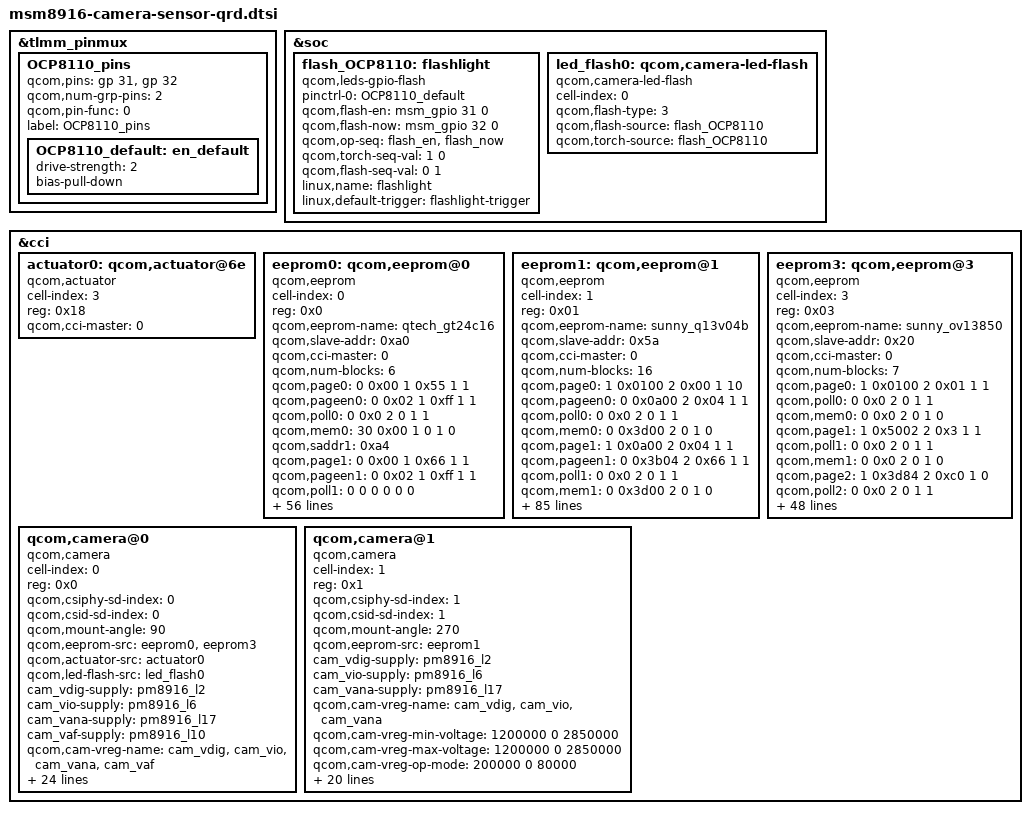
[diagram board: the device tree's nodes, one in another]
/*
 * Copyright (c) 2014, The Linux Foundation. All rights reserved.
 *
 * This program is free software; you can redistribute it and/or modify
 * it under the terms of the GNU General Public License version 2 and
 * only version 2 as published by the Free Software Foundation.
 *
 * This program is distributed in the hope that it will be useful,
 * but WITHOUT ANY WARRANTY; without even the implied warranty of
 * MERCHANTABILITY or FITNESS FOR A PARTICULAR PURPOSE.  See the
 * GNU General Public License for more details.
 */

&tlmm_pinmux {
	OCP8110_pins {
		qcom,pins = <&gp 31>, <&gp 32>;
		qcom,num-grp-pins = <2>;
		qcom,pin-func = <0>;
		label = "OCP8110_pins";
		OCP8110_default: en_default {
			  drive-strength = <2>;
			  bias-pull-down;
		};
	};
};

&soc {
	flash_OCP8110:flashlight {
		compatible = "qcom,leds-gpio-flash";
		status = "okay";
		pinctrl-names = "flash_default";
		pinctrl-0 = <&OCP8110_default>;
		qcom,flash-en = <&msm_gpio 31 0>;
		qcom,flash-now = <&msm_gpio 32 0>;
		qcom,op-seq = "flash_en", "flash_now";
		qcom,torch-seq-val = <1 0>;//1//1.0
		qcom,flash-seq-val = <0 1>;//1//1.1
		linux,name = "flashlight";
		linux,default-trigger = "flashlight-trigger";
	};

	led_flash0: qcom,camera-led-flash {
		cell-index = <0>;
		compatible = "qcom,camera-led-flash";
		qcom,flash-type = <3>;
		qcom,flash-source = <&flash_OCP8110>;
		qcom,torch-source = <&flash_OCP8110>;
	};
};

&cci {
	actuator0: qcom,actuator@6e {
		cell-index = <3>;
		reg = <0x18>;
		compatible = "qcom,actuator";
		qcom,cci-master = <0>;
	};

	eeprom0: qcom,eeprom@0 {
		cell-index = <0>;
		reg = <0x0>;
		qcom,eeprom-name = "qtech_gt24c16";
		compatible = "qcom,eeprom";
		qcom,slave-addr = <0xa0>;
		qcom,cci-master = <0>;
		
		qcom,num-blocks = <6>;
		
		qcom,page0 = <0 0x00 1 0x55 1 1>;
		qcom,pageen0 = <0 0x02 1 0xff 1 1>;
		qcom,poll0 = <0 0x0 2 0 1 1>;
		qcom,mem0 = <30 0x00 1 0 1 0>;

		qcom,saddr1 = <0xa4>;
		qcom,page1 = <0 0x00 1 0x66 1 1>;
		qcom,pageen1 = <0 0x02 1 0xff 1 1>;
		qcom,poll1 = <0 0 0 0 0 0>;
		qcom,mem1 = <255 0x00 1 0 1 0>;
		
		qcom,saddr2 = <0xa6>;
		qcom,page2 = <0 0x00 1 0x77 1 1>;
		qcom,pageen2 = <0 0x02 1 0xff 1 1>;
		qcom,poll2 = <0 0 0 0 0 0>;
		qcom,mem2 = <255 0x00 1 0 1 0>;

		qcom,saddr3 = <0xa8>;
		qcom,page3 = <0 0x00 1 0x88 1 1>;
		qcom,pageen3 = <0 0x02 1 0xff 1 1>;
		qcom,poll3 = <0 0 0 0 0 0>;
		qcom,mem3 = <255 0x00 1 0 1 0>;
		
		qcom,saddr4 = <0xaa>;
		qcom,page4 = <0 0x00 1 0x99 1 1>;
		qcom,pageen4 = <0 0x02 1 0xff 1 1>;
		qcom,poll4 = <0 0 0 0 0 0>;
		qcom,mem4 = <255 0x00 1 0 1 0>;
		
		qcom,saddr5 = <0xac>;
		qcom,page5 = <0 0x00 1 0x11 1 1>;
		qcom,pageen5 = <0 0x02 1 0xff 1 1>;
		qcom,poll5 = <0 0 0 0 0 0>;
		qcom,mem5 = <85 0x00 1 0 1 0>;
		
		cam_vdig-supply = <&pm8916_l2>;
		cam_vio-supply = <&pm8916_l6>;
		cam_vana-supply = <&pm8916_l17>;
		cam_vaf-supply = <&pm8916_l10>;
		qcom,cam-vreg-name = "cam_vdig", "cam_vio", "cam_vana",
							"cam_vaf";
		qcom,cam-vreg-min-voltage = <1200000 0 2850000 2800000>;
		qcom,cam-vreg-max-voltage = <1200000 0 2850000 2800000>;
		qcom,cam-vreg-op-mode = <200000 0 80000 100000>;
		pinctrl-names = "cam_default", "cam_suspend";
		pinctrl-0 = <&cam_sensor_mclk0_default &cam_sensor_rear_default>;
		pinctrl-1 = <&cam_sensor_mclk0_sleep &cam_sensor_rear_sleep>;
		gpios = <&msm_gpio 26 0>,
				<&msm_gpio 119 0>,
				<&msm_gpio 34 0>,
				<&msm_gpio 36 0>;
		qcom,gpio-reset = <1>;
		qcom,gpio-standby = <2>;
		qcom,gpio-af-pwdm = <3>;
		qcom,gpio-req-tbl-num = <0 1 2 3>;
		qcom,gpio-req-tbl-flags = <1 0 0 0 >;
		qcom,gpio-req-tbl-label = "CAMIF_MCLK",
				"CAM_RESET1",
				"CAM_STANDBY",
				"CAM_AF_PWDM";
				
		qcom,cam-power-seq-type = "sensor_vreg",
			"sensor_vreg", "sensor_vreg",
			"sensor_gpio",
			"sensor_clk",
			"sensor_gpio", "sensor_gpio";
		qcom,cam-power-seq-val = "cam_vio",
			"cam_vana", "cam_vdig",
			"sensor_gpio_vdig",
			"sensor_cam_mclk",
			"sensor_gpio_reset",
			"sensor_gpio_standby";
		qcom,cam-power-seq-cfg-val = <1 1 1 1 23880000 1  1>;
		qcom,cam-power-seq-delay = <1 1 5 5 5 5 10>;
		
		status = "ok";
		clocks = <&clock_gcc clk_mclk0_clk_src>,
				<&clock_gcc clk_gcc_camss_mclk0_clk>;
		clock-names = "cam_src_clk", "cam_clk";

	};
	
	eeprom1: qcom,eeprom@1 {
		cell-index = <1>;
		reg = <0x01>;
		qcom,eeprom-name = "sunny_q13v04b";
		compatible = "qcom,eeprom";
		qcom,slave-addr = <0x5a>;
		qcom,cci-master = <0>;

		qcom,num-blocks = <16>;
		
		qcom,page0 = <1 0x0100 2 0x00 1 10>;
		qcom,pageen0 = <0 0x0a00 2 0x04 1 1>;
		qcom,poll0 = <0 0x0 2 0 1 1>;
		qcom,mem0 = <0 0x3d00 2 0 1 0>;

		qcom,page1 = <1  0x0a00 2 0x04 1 1>;
		qcom,pageen1 = <0 0x3b04 2 0x66 1 1>;
		qcom,poll1 = <0 0x0 2 0 1 1>;
		qcom,mem1 = <0 0x3d00 2 0 1 0>;
		
		qcom,page2 = <1 0x0a02 2 0x04 1 1>;//set page
		qcom,pageen2 = <0 0x3b06 2 0xe6 1 1>;
		qcom,poll2 = <0 0x0 2 0 1 1>;
		qcom,mem2 = <0 0x3d00 2 0 1 0>;

		qcom,page3 = <1 0x0a00 2 0x01 1 10>;
		qcom,pageen3 = <0 0x3b06 2 0xe6 1 1>;
		qcom,poll3 = <0 0x0 2 0 1 1>;
		qcom,mem3 = <64 0x0a04 2 0 1 1>;
		
		qcom,page4 = <1 0x0a02 2 0x05 1 1>;
		qcom,pageen4 = <0 0x3b0b 2 0x76 1 1>;
		qcom,poll4 = <0 0x0 2 0 1 1>;
		qcom,mem4 = <64 0x0a04 2 0 1 1>;
		
		qcom,page5 = <0 0x0a02 2 0x05 1 1>;
		qcom,pageen5 = <0 0x3b0e 2 0x1d 1 1>;
		qcom,poll5 = <0 0x0 2 0 1 1>;
		qcom,mem5 = <0 0x0a04 2 0 1 1>;

		qcom,page6 = <1 0x0a02 2 0x06 1 1>;
		qcom,pageen6 = <0 0x3b0e 2 0x1d 1 1>;
		qcom,poll6 = <0 0x0 2 0 1 1>;
		qcom,mem6 = <64 0x0a04 2 0 1 1>;
			
		qcom,page7 = <1 0x0a02 2 0x07 1 1>;
		qcom,pageen7 = <0 0x3b10 2 0xfd 1 1>;
		qcom,poll7 = <0 0x0 2 0 1 1>;
		qcom,mem7 = <64 0x0a04 2 0 1 1>;
		
		qcom,page8 = <1 0x0a02 2 0x08 1 1>;
		qcom,pageen8 = <0 0x3a00 2 0x01 1 1>;
		qcom,poll8 = <0 0x0 2 0 1 1>;
		qcom,mem8 = <64 0x0a04 2 0 1 1>;
		
		qcom,page9 = <1 0x0a02 2 0x09 1 1>;
		qcom,pageen9 = <0 0x3a00 2 0x00 1 10>;
		qcom,mem9 = <64 0x0a04 2 0 1 1>;
		qcom,poll9 = <0 0x0 2 0 1 1>;

		qcom,page10 = <1 0x0a02 2 0x0a 1 1>;
		qcom,pageen10 = <0 0x3a00 2 0x00 1 10>;
		qcom,mem10 = <64 0x0a04  2 0 1 1>;
		qcom,poll10 = <0 0x0 2 0 1 1>;

		qcom,page11 = <1 0x0a02 2 0x0e 1 1>;
		qcom,pageen11 = <0 0x3a00 2 0x00 1 10>;
		qcom,mem11 = <64 0x0a04  2 0 1 1>;
		qcom,poll11 = <0 0x0 2 0 1 1>;

		qcom,page12 = <1 0x3a02 2 0x00 1 1>; 
		qcom,pageen12 = <0 0x3a00 2 0x00 1 10>;
		qcom,mem12 = <0 0x3a04  2 0 1 1>;
		qcom,poll12 = <0 0x0 2 0 1 1>;

		qcom,page13 = <1 0x0a00 2 0x04 1 1>;
		qcom,pageen13 = <0 0x3a00 2 0x00 1 10>;
		qcom,mem13= <0 0x0a04  2 0 1 1>;
		qcom,poll13 = <0 0x0 2 0 1 1>;
		
		qcom,page14 = <1 0x0a00 2 0x00 1 1>;
		qcom,pageen14 = <0 0x0a00 2 0x00 1 10>;
		qcom,mem14= <0 0x0a04  2 0 1 1>;
		qcom,poll14 = <0 0x0 2 0 1 1>;

		qcom,page15 = <1 0x0100 2 0x01 1 1>;
		qcom,pageen15 = <0 0x0a00 2 0x00 1 10>;
		qcom,mem15= <0 0x0a04  2 0 1 1>;
		qcom,poll15 = <0 0x0 2 0 1 1>;

		cam_vdig-supply = <&pm8916_l2>;
		cam_vana-supply = <&pm8916_l17>;
		cam_vio-supply = <&pm8916_l6>;
		qcom,cam-vreg-name = "cam_vdig", "cam_vio", "cam_vana";
		qcom,cam-vreg-min-voltage = <1200000 0 2850000>;
		qcom,cam-vreg-max-voltage = <1200000 0 2850000>;
		qcom,cam-vreg-op-mode = <200000 0 80000>;
		pinctrl-names = "cam_default", "cam_suspend";
		pinctrl-0 = <&cam_sensor_mclk1_default &cam_sensor_front_default>;
		pinctrl-1 = <&cam_sensor_mclk1_sleep &cam_sensor_front_sleep>;
		gpios = <&msm_gpio 27 0>,
			<&msm_gpio 119 0>,
			<&msm_gpio 28 0>;
		qcom,gpio-reset = <1>;
		qcom,gpio-standby = <2>;
		qcom,gpio-req-tbl-num = <0 1 2>;
		qcom,gpio-req-tbl-flags = <1 0 0>;
		qcom,gpio-req-tbl-label = "CAMIF_MCLK",
			"SCAM_RESET",
			"SCAM_STANDBY";

		qcom,cam-power-seq-type = "sensor_vreg",
			"sensor_vreg", "sensor_vreg",
			"sensor_gpio", "sensor_gpio",
			"sensor_clk";
		qcom,cam-power-seq-val = "cam_vio",
			"cam_vana", "cam_vdig",
			"sensor_gpio_reset",
			"sensor_gpio_standby",
			"sensor_cam_mclk" ;
		qcom,cam-power-seq-cfg-val = <1 1 1 1 1 24000000>;
		qcom,cam-power-seq-delay = <10 10 10 10 10 5>;

		clocks = <&clock_gcc clk_mclk1_clk_src>,
			<&clock_gcc clk_gcc_camss_mclk1_clk>;
		clock-names = "cam_src_clk", "cam_clk";
	};

	eeprom3: qcom,eeprom@3 {
		cell-index = <3>;
		reg = <0x03>;
		qcom,eeprom-name = "sunny_ov13850";
		compatible = "qcom,eeprom";
		qcom,slave-addr = <0x20>;
		qcom,cci-master = <0>;
		qcom,num-blocks = <7>;

		qcom,page0 = <1 0x0100 2 0x01 1 1>;
		qcom,poll0 = <0 0x0 2 0 1 1>;
		qcom,mem0 = <0 0x0 2 0 1 0>;
		qcom,page1 = <1 0x5002 2 0x3 1 1>;
		qcom,poll1 = <0 0x0 2 0 1 1>;
		qcom,mem1 = <0 0x0 2 0 1 0>;
		qcom,page2 = <1 0x3d84 2 0xc0 1 0>;
		qcom,poll2 = <0 0x0 2 0 1 1>;
		qcom,mem2 = <0 0x0 2 0 1 0>;
		qcom,page3 = <1 0x3d88 2 0x7220 2 0>;
		qcom,poll3 = <0 0x0 2 0 1 1>;
		qcom,mem3 = <0 0x0 2 0 1 0>;
		qcom,page4 = <1 0x3d8a 2 0x7369 2 0>;
		qcom,poll4 = <0 0x0 2 0 1 1>;
		qcom,mem4 = <0 0x0 2 0 1 0>;
		qcom,page5 = <1 0x3d81 2 0x01 1 15>;
		qcom,poll5 = <0 0x0 2 0 1 1>;
		qcom,mem5 = <412 0x7220 2 0 1 0>;
		qcom,page6 = <1 0x5002 2 0x1 1 1>;
		qcom,poll6 = <0 0x0 2 0 1 1>;
		qcom,mem6 = <0 0x0 2 0 1 0>;

		cam_vdig-supply = <&pm8916_l2>;
		cam_vio-supply = <&pm8916_l6>;
		cam_vana-supply = <&pm8916_l17>;
		cam_vaf-supply = <&pm8916_l10>;
		qcom,cam-vreg-name = "cam_vdig", "cam_vio", "cam_vana",
							"cam_vaf";
		qcom,cam-vreg-min-voltage = <1200000 0 2850000 2800000>;
		qcom,cam-vreg-max-voltage = <1200000 0 2850000 2800000>;
		qcom,cam-vreg-op-mode = <200000 0 80000 100000>;
		pinctrl-names = "cam_default", "cam_suspend";
		pinctrl-0 = <&cam_sensor_mclk0_default &cam_sensor_rear_default>;
		pinctrl-1 = <&cam_sensor_mclk0_sleep &cam_sensor_rear_sleep>;
		gpios = <&msm_gpio 26 0>,
				<&msm_gpio 119 0>,
				<&msm_gpio 34 0>,
				<&msm_gpio 36 0>;
		qcom,gpio-reset = <1>;
		qcom,gpio-standby = <2>;
		qcom,gpio-af-pwdm = <3>;
		qcom,gpio-req-tbl-num = <0 1 2 3>;
		qcom,gpio-req-tbl-flags = <1 0 0 0 >;
		qcom,gpio-req-tbl-label = "CAMIF_MCLK",
				"CAM_RESET1",
				"CAM_STANDBY",
				"CAM_AF_PWDM";
				
		qcom,cam-power-seq-type = "sensor_vreg",
			"sensor_vreg", "sensor_vreg",
			"sensor_gpio",
			"sensor_clk",
			"sensor_gpio", "sensor_gpio";
		qcom,cam-power-seq-val = "cam_vio",
			"cam_vana", "cam_vdig",
			"sensor_gpio_vdig",
			"sensor_cam_mclk",
			"sensor_gpio_reset",
			"sensor_gpio_standby";
		qcom,cam-power-seq-cfg-val = <1 1 1 1 23880000 1  1>;
		qcom,cam-power-seq-delay = <1 1 5 5 5 5 10>;
		
		status = "ok";
		clocks = <&clock_gcc clk_mclk0_clk_src>,
				<&clock_gcc clk_gcc_camss_mclk0_clk>;
		clock-names = "cam_src_clk", "cam_clk";

	};




	qcom,camera@0 {
		cell-index = <0>;
		compatible = "qcom,camera";
		reg = <0x0>;
		qcom,csiphy-sd-index = <0>;
		qcom,csid-sd-index = <0>;
		qcom,mount-angle = <90>;
		qcom,eeprom-src =<&eeprom0 &eeprom3>;
		qcom,actuator-src = <&actuator0>;
		qcom,led-flash-src = <&led_flash0>;
		cam_vdig-supply = <&pm8916_l2>;
		cam_vio-supply = <&pm8916_l6>;
		cam_vana-supply = <&pm8916_l17>;
		cam_vaf-supply = <&pm8916_l10>;
		qcom,cam-vreg-name = "cam_vdig", "cam_vio", "cam_vana",
							"cam_vaf";
		qcom,cam-vreg-min-voltage = <1200000 0 2850000 2800000>;
		qcom,cam-vreg-max-voltage = <1200000 0 2850000 2800000>;
		qcom,cam-vreg-op-mode = <200000 0 80000 100000>;
		pinctrl-names = "cam_default", "cam_suspend";
		pinctrl-0 = <&cam_sensor_mclk0_default &cam_sensor_rear_default>;
		pinctrl-1 = <&cam_sensor_mclk0_sleep &cam_sensor_rear_sleep>;
		gpios = <&msm_gpio 26 0>,
				<&msm_gpio 119 0>,
				<&msm_gpio 34 0>,
				<&msm_gpio 36 0>;
		qcom,gpio-reset = <1>;
		qcom,gpio-standby = <2>;
		qcom,gpio-af-pwdm = <3>;
		qcom,gpio-req-tbl-num = <0 1 2 3 >;
		qcom,gpio-req-tbl-flags = <1 0 0 0 >;
		qcom,gpio-req-tbl-label = "CAMIF_MCLK",
				"CAM_RESET1",
				"CAM_STANDBY",
				"CAM_AF_PWDM";
		qcom,sensor-position = <0>;
		qcom,sensor-mode = <0>;
		qcom,cci-master = <0>;
		qcom,mclk-23880000;
		status = "ok";
		clocks = <&clock_gcc clk_mclk0_clk_src>,
				<&clock_gcc clk_gcc_camss_mclk0_clk>;
		clock-names = "cam_src_clk", "cam_clk";
	};

	qcom,camera@1 {
		cell-index = <1>;
		compatible = "qcom,camera";
		reg = <0x1>;
		qcom,csiphy-sd-index = <1>;
		qcom,csid-sd-index = <1>;
		qcom,mount-angle = <270>;
		qcom,eeprom-src = <&eeprom1>;
		cam_vdig-supply = <&pm8916_l2>;
		cam_vio-supply = <&pm8916_l6>;
		cam_vana-supply = <&pm8916_l17>;
		qcom,cam-vreg-name = "cam_vdig", "cam_vio", "cam_vana";
		qcom,cam-vreg-min-voltage = <1200000 0 2850000>;
		qcom,cam-vreg-max-voltage = <1200000 0 2850000>;
		qcom,cam-vreg-op-mode = <200000 0 80000>;
		pinctrl-names = "cam_default", "cam_suspend";
		pinctrl-0 = <&cam_sensor_mclk1_default &cam_sensor_front_default>;
		pinctrl-1 = <&cam_sensor_mclk1_sleep &cam_sensor_front_sleep>;
		gpios = <&msm_gpio 27 0>,
				<&msm_gpio 119 0>,
				<&msm_gpio 28 0>,
				<&msm_gpio 114 0>,
				<&msm_gpio 110 0>;
		qcom,gpio-reset = <1>;
		qcom,gpio-standby = <2>;
		qcom,gpio-vdig = <3>;
		qcom,gpio-vana = <4>;
		qcom,gpio-req-tbl-num = <0 1 2 3 4>;
		qcom,gpio-req-tbl-flags = <1 0 0 0 0>;
		qcom,gpio-req-tbl-label = "CAMIF_MCLK",
				"CAM_RESET",
				"CAM_STANDBY",
				"CAM_VDIG",
				"CAM_VANA";
		qcom,sensor-position = <1>;
		qcom,sensor-mode = <0>;
		qcom,cci-master = <0>;
		qcom,mclk-23880000;
		status = "ok";
		clocks = <&clock_gcc clk_mclk1_clk_src>,
				<&clock_gcc clk_gcc_camss_mclk1_clk>;
		clock-names = "cam_src_clk", "cam_clk";
	};
};


